# apollo3 register map
Vendor: Ambiq Micro; Series: Apollo; File version: 1.0
CPU: CM4 r1p0, little endian, MPU, FPU, 3 interrupt priority bits
Registers are 32-bit, read-write, reset 0x0 unless marked. A register's access mark holds for its fields unless they carry their own. Offsets are from the block's base; [hi:lo] are bit positions; {n}, {i} and the like mark numbered series; 'fields as' and 'values as' point back to an identical list.

## ADC — Analog Digital Converter Control
Base 0x50010000
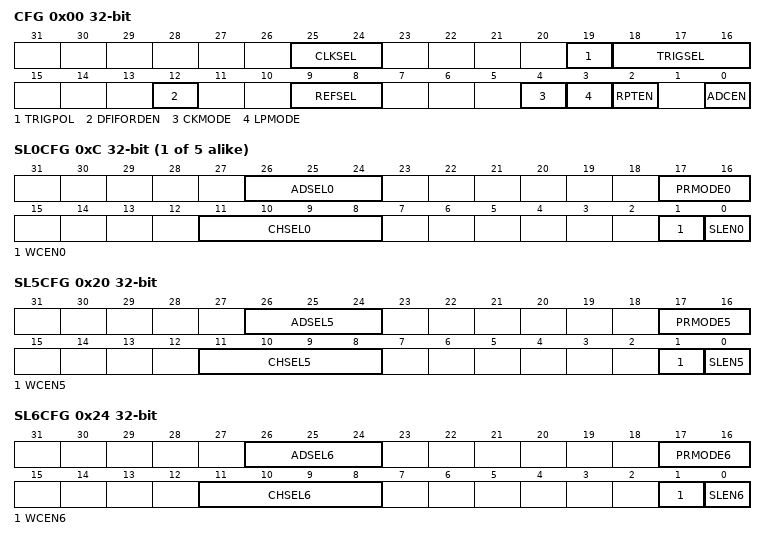
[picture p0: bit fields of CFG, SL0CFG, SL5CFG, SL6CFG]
0x00 CFG — Configuration Register
  [25:24] CLKSEL — Select the source and frequency for the ADC clock. All values not enumerated below are undefined.
    0=OFF (Off mode. The HFRC or HFRC_DIV2 clock must be selected for the ADC to function. The ADC controller automatically shuts off the clock in it's low power modes. When setting ADCEN to '0', the CLKSEL should remain set to one of the two clock selects for proper power down sequencing. value.); 1=HFRC (HFRC Core Clock divided by (CORESEL+1) value.); 2=HFRC_DIV2 (HFRC Core Clock / 2 further divided by (CORESEL+1) value.)
  [19] TRIGPOL — This bit selects the ADC trigger polarity for external off chip triggers.
    0=RISING_EDGE (Trigger on rising edge. value.); 1=FALLING_EDGE (Trigger on falling edge. value.)
  [18:16] TRIGSEL — Select the ADC trigger source.
    {v}=EXT{v} (Off chip External Trigger{v} (ADC_ET{v}) value.) (v=0..3); 4=VCOMP (Voltage Comparator Output value.); 7=SWT (Software Trigger value.)
  [12] DFIFORDEN — Destructive FIFO Read Enable. Setting this will enable FIFO pop upon reading the FIFOPR register.
    0=DIS (Destructive Reads are prevented. Reads to the FIFOPR register will not POP an entry off the FIFO. value.); 1=EN (Reads to the FIFOPR registger will automatically pop an entry off the FIFO. value.)
  [9:8] REFSEL — Select the ADC reference voltage.
    0=INT2P0 (Internal 2.0V Bandgap Reference Voltage value.); 1=INT1P5 (Internal 1.5V Bandgap Reference Voltage value.); 2=EXT2P0 (Off Chip 2.0V Reference value.); 3=EXT1P5 (Off Chip 1.5V Reference value.)
  [4] CKMODE — Clock mode register
    0=LPCKMODE (Disable the clock between scans for LPMODE0. Set LPCKMODE to 0x1 while configuring the ADC. value.); 1=LLCKMODE (Low Latency Clock Mode. When set, HFRC and the adc_clk will remain on while in functioning in LPMODE0. value.)
  [3] LPMODE — Select power mode to enter between active scans.
    0=MODE0 (Low Power Mode 0. Leaves the ADC fully powered between scans with minimum latency between a trigger event and sample data collection. value.); 1=MODE1 (Low Power Mode 1. Powers down all circuity and clocks associated with the ADC until the next trigger event. Between scans, the reference buffer requires up to 50us of delay from a scan trigger event before the conversion will commence while operating in this mode. value.)
  [2] RPTEN — This bit enables Repeating Scan Mode.
    0=SINGLE_SCAN (In Single Scan Mode, the ADC will complete a single scan upon each trigger event. value.); 1=REPEATING_SCAN (In Repeating Scan Mode, the ADC will complete it's first scan upon the initial trigger event and all subsequent scans will occur at regular intervals defined by the configuration programmed for the CTTMRA3 internal timer until the timer is disabled or the ADC is disabled. When disabling the ADC (setting ADCEN to '0'), the RPTEN bit should be cleared. value.)
  [0] ADCEN — This bit enables the ADC module. While the ADC is enabled, the ADCCFG and SLOT Configuration regsiter settings must remain stable and unchanged. All configuration register settings, slot configuration settings and window comparison settings should be written prior to setting the ADCEN bit to '1'.
    0=DIS (Disable the ADC module. value.); 1=EN (Enable the ADC module. value.)
0x04 STAT — ADC Power Status
  [0] PWDSTAT — Indicates the power-status of the ADC.
    0=ON (Powered on. value.); 1=POWERED_DOWN (ADC Low Power Mode 1. value.)
0x08 SWT — Software trigger
  [7:0] SWT — Writing 0x37 to this register generates a software trigger.
    55=GEN_SW_TRIGGER (Writing this value generates a software trigger. value.)
{0xC+4i} SL{i}CFG (i=0..4) — Slot {i} Configuration Register
  [26:24] ADSEL{i} — Select the number of measurements to average in the accumulate divide module for this slot.
    0=AVG_1_MSRMT (Average in 1 measurement in the accumulate divide module for this slot. value.); 1=AVG_2_MSRMTS (Average in 2 measurements in the accumulate divide module for this slot. value.); 2=AVG_4_MSRMTS (Average in 4 measurements in the accumulate divide module for this slot. value.); 3=AVG_8_MSRMT (Average in 8 measurements in the accumulate divide module for this slot. value.); 4=AVG_16_MSRMTS (Average in 16 measurements in the accumulate divide module for this slot. value.); 5=AVG_32_MSRMTS (Average in 32 measurements in the accumulate divide module for this slot. value.); 6=AVG_64_MSRMTS (Average in 64 measurements in the accumulate divide module for this slot. value.); 7=AVG_128_MSRMTS (Average in 128 measurements in the accumulate divide module for this slot. value.)
  [17:16] PRMODE{i} — Set the Precision Mode For Slot.
    0=P14B (14-bit precision mode value.); 1=P12B (12-bit precision mode value.); 2=P10B (10-bit precision mode value.); 3=P8B (8-bit precision mode value.)
  [11:8] CHSEL{i} — Select one of the 14 channel inputs for this slot.
    0=SE0 (single ended external GPIO connection to pad16. value.); 1=SE1 (single ended external GPIO connection to pad29. value.); 2=SE2 (single ended external GPIO connection to pad11. value.); {v}=SE{v} (single ended external GPIO connection to pad{v+28}. value.) (v=3..7); 8=SE8 (single ended external GPIO connection to pad13. value.); 9=SE9 (single ended external GPIO connection to pad12. value.); 10=DF0 (differential external GPIO connections to pad12(N) and pad13(P). value.); 11=DF1 (differential external GPIO connections to pad15(N) and pad14(P). value.); 12=TEMP (internal temperature sensor. value.); 13=BATT (internal voltage divide-by-3 connection. value.); 14=VSS (Input VSS value.)
  [1] WCEN{i} — This bit enables the window compare function for slot {i}.
    1=WCEN (Enable the window compare for slot {i}. value.)
  [0] SLEN{i} — This bit enables slot {i} for ADC conversions.
    1=SLEN (Enable slot {i} for ADC conversions. value.)
0x20 SL5CFG — Slot 5 Configuration Register
  [26:24] ADSEL5 — Select number of measurements to average in the accumulate divide module for this slot.
    values as SL0CFG.ADSEL{i}
  [17:16] PRMODE5 — Set the Precision Mode For Slot.
    values as SL0CFG.PRMODE{i}
  [11:8] CHSEL5 — Select one of the 14 channel inputs for this slot.
    values as SL0CFG.CHSEL{i}
  [1] WCEN5 — This bit enables the window compare function for slot 5.
    1=WCEN (Enable the window compare for slot 5. value.)
  [0] SLEN5 — This bit enables slot 5 for ADC conversions.
    1=SLEN (Enable slot 5 for ADC conversions. value.)
0x24 SL6CFG — Slot 6 Configuration Register
  [26:24] ADSEL6 — Select the number of measurements to average in the accumulate divide module for this slot.
    values as SL0CFG.ADSEL{i}
  [17:16] PRMODE6 — Set the Precision Mode For Slot.
    values as SL0CFG.PRMODE{i}
  [11:8] CHSEL6 — Select one of the 14 channel inputs for this slot.
    values as SL0CFG.CHSEL{i}
  [1] WCEN6 — This bit enables the window compare function for slot 6.
    1=WCEN (Enable the window compare for slot 6. value.)
  [0] SLEN6 — This bit enables slot 6 for ADC conversions.
    1=SLEN (Enable slot 6 for ADC conversions. value.)
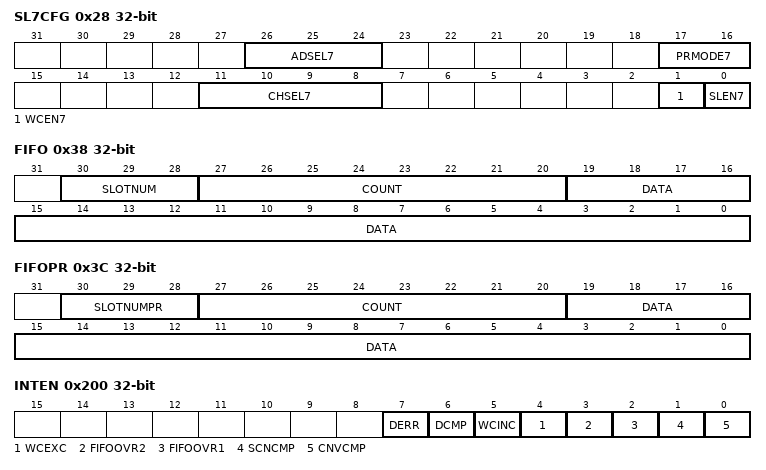
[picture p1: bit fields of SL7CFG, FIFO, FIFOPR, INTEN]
0x28 SL7CFG — Slot 7 Configuration Register
  [26:24] ADSEL7 — Select the number of measurements to average in the accumulate divide module for this slot.
    values as SL0CFG.ADSEL{i}
  [17:16] PRMODE7 — Set the Precision Mode For Slot.
    values as SL0CFG.PRMODE{i}
  [11:8] CHSEL7 — Select one of the 14 channel inputs for this slot.
    values as SL0CFG.CHSEL{i}
  [1] WCEN7 — This bit enables the window compare function for slot 7.
    1=WCEN (Enable the window compare for slot 7. value.)
  [0] SLEN7 — This bit enables slot 7 for ADC conversions.
    1=SLEN (Enable slot 7 for ADC conversions. value.)
0x2C WULIM — Window Comparator Upper Limits Register
  [19:0] ULIM — Sets the upper limit for the window comparator.
0x30 WLLIM — Window Comparator Lower Limits Register
  [19:0] LLIM — Sets the lower limit for the window comparator.
0x34 SCWLIM — Scale Window Comparator Limits
  [0] SCWLIMEN — Scale the window limits compare values per precision mode. When set to 0x0 (default), the values in the 20-bit limits registers will compare directly with the FIFO values regardless of the precision mode the slot is configured to. When set to 0x1, the compare values will be divided by the difference in precision bits while performing the window limit comparisons.
0x38 FIFO — FIFO Data and Valid Count Register
  [30:28] SLOTNUM — Slot number associated with this FIFO data.
  [27:20] COUNT — Number of valid entries in the ADC FIFO.
  [19:0] DATA — Oldest data in the FIFO.
0x3C FIFOPR — FIFO Data and Valid Count Register
  [30:28] SLOTNUMPR — Slot number associated with this FIFO data.
  [27:20] COUNT — Number of valid entries in the ADC FIFO.
  [19:0] DATA — Oldest data in the FIFO.
0x200 INTEN — ADC Interrupt registers: Enable
  [7] DERR — DMA Error Condition
    1=DMAERROR (DMA Error Condition Occurred value.)
  [6] DCMP — DMA Transfer Complete
    1=DMACOMPLETE (DMA Completed a transfer value.)
  [5] WCINC — Window comparator voltage incursion interrupt.
    1=WCINCINT (Window comparitor voltage incursion interrupt. value.)
  [4] WCEXC — Window comparator voltage excursion interrupt.
    1=WCEXCINT (Window comparitor voltage excursion interrupt. value.)
  [3] FIFOOVR2 — FIFO 100 percent full interrupt.
    1=FIFOFULLINT (FIFO 100 percent full interrupt. value.)
  [2] FIFOOVR1 — FIFO 75 percent full interrupt.
    1=FIFO75INT (FIFO 75 percent full interrupt. value.)
  [1] SCNCMP — ADC scan complete interrupt.
    1=SCNCMPINT (ADC scan complete interrupt. value.)
  [0] CNVCMP — ADC conversion complete interrupt.
    1=CNVCMPINT (ADC conversion complete interrupt. value.)
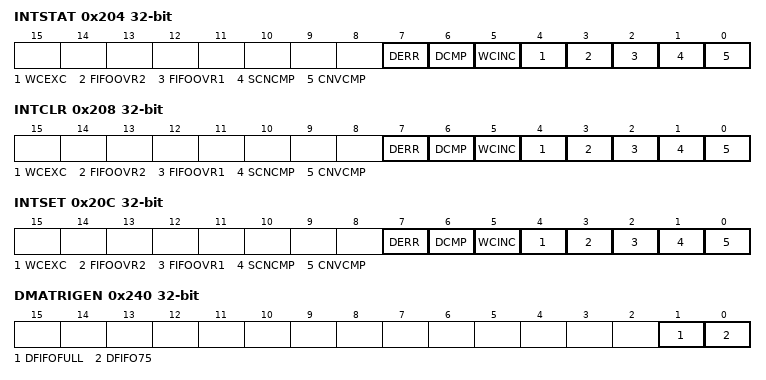
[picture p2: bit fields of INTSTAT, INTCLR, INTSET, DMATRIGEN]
0x204 INTSTAT — ADC Interrupt registers: Status
  fields as INTEN
0x208 INTCLR — ADC Interrupt registers: Clear
  fields as INTEN
0x20C INTSET — ADC Interrupt registers: Set
  fields as INTEN
0x240 DMATRIGEN — DMA Trigger Enable Register
  [1] DFIFOFULL — Trigger DMA upon FIFO 100 percent Full
  [0] DFIFO75 — Trigger DMA upon FIFO 75 percent Full
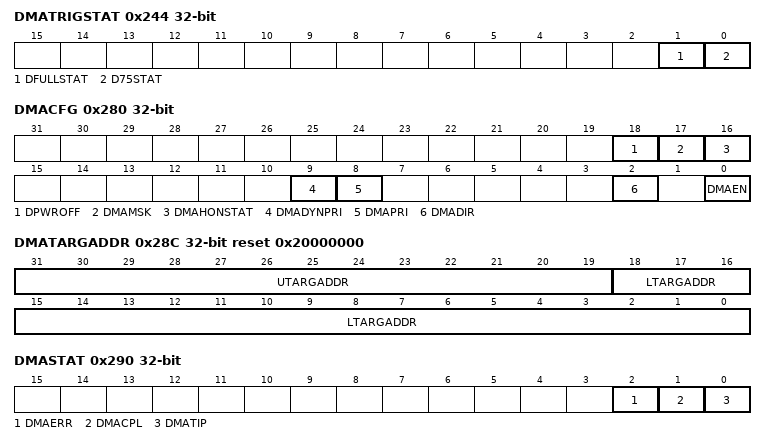
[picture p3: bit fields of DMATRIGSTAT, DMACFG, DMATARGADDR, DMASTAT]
0x244 DMATRIGSTAT — DMA Trigger Status Register
  [1] DFULLSTAT — Triggered DMA from FIFO 100 percent Full
  [0] D75STAT — Triggered DMA from FIFO 75 percent Full
0x280 DMACFG — DMA Configuration Register
  [18] DPWROFF — Power Off the ADC System upon DMACPL.
  [17] DMAMSK — Mask the FIFOCNT and SLOTNUM when transferring FIFO contents to memory
    0=DIS (FIFO Contents are copied directly to memory without modification. value.); 1=EN (Only the FIFODATA contents are copied to memory on DMA transfers. The SLOTNUM and FIFOCNT contents are cleared to zero. value.)
  [16] DMAHONSTAT — Halt New ADC conversions until DMA Status DMAERR and DMACPL Cleared.
    0=DIS (ADC conversions will continue regardless of DMA status register value.); 1=EN (ADC conversions will not progress if DMAERR or DMACPL bits in DMA status register are set. value.)
  [9] DMADYNPRI — Enables dynamic priority based on FIFO fullness. When FIFO is full, priority is automatically set to HIGH. Otherwise, DMAPRI is used.
    0=DIS (Disable dynamic priority (use DMAPRI setting only) value.); 1=EN (Enable dynamic priority value.)
  [8] DMAPRI — Sets the Priority of the DMA request
    0=LOW (Low Priority (service as best effort) value.); 1=HIGH (High Priority (service immediately) value.)
  [2] DMADIR — Direction
    0=P2M (Peripheral to Memory (SRAM) transaction value.); 1=M2P (Memory to Peripheral transaction value.)
  [0] DMAEN — DMA Enable
    0=DIS (Disable DMA Function value.); 1=EN (Enable DMA Function value.)
0x288 DMATOTCOUNT — DMA Total Transfer Count
  [17:2] TOTCOUNT — Total Transfer Count
0x28C DMATARGADDR reset 0x20000000 — DMA Target Address Register
  [31:19] UTARGADDR — SRAM Target
  [18:0] LTARGADDR — DMA Target Address
0x290 DMASTAT — DMA Status Register
  [2] DMAERR — DMA Error
  [1] DMACPL — DMA Transfer Complete
  [0] DMATIP — DMA Transfer In Progress

## Notices in the file
Copyright (C) 2012-2014 ARM Limited. All rights reserved.
Purpose: System Viewer Description (SVD) Example (Schema Version 1.1)
This is a description of a none-existent and incomplete device
for demonstration purposes only.
Redistribution and use in source and binary forms, with or without
modification, are permitted provided that the following conditions are met:
- Redistributions of source code must retain the above copyright
notice, this list of conditions and the following disclaimer.
- Redistributions in binary form must reproduce the above copyright
notice, this list of conditions and the following disclaimer in the
documentation and/or other materials provided with the distribution.
- Neither the name of ARM nor the names of its contributors may be used
to endorse or promote products derived from this software without
specific prior written permission.
THIS SOFTWARE IS PROVIDED BY THE COPYRIGHT HOLDERS AND CONTRIBUTORS "AS IS"
AND ANY EXPRESS OR IMPLIED WARRANTIES, INCLUDING, BUT NOT LIMITED TO, THE
IMPLIED WARRANTIES OF MERCHANTABILITY AND FITNESS FOR A PARTICULAR PURPOSE
ARE DISCLAIMED. IN NO EVENT SHALL COPYRIGHT HOLDERS AND CONTRIBUTORS BE
LIABLE FOR ANY DIRECT, INDIRECT, INCIDENTAL, SPECIAL, EXEMPLARY, OR
CONSEQUENTIAL DAMAGES (INCLUDING, BUT NOT LIMITED TO, PROCUREMENT OF
SUBSTITUTE GOODS OR SERVICES; LOSS OF USE, DATA, OR PROFITS; OR BUSINESS
INTERRUPTION) HOWEVER CAUSED AND ON ANY THEORY OF LIABILITY, WHETHER IN
CONTRACT, STRICT LIABILITY, OR TORT (INCLUDING NEGLIGENCE OR OTHERWISE)
ARISING IN ANY WAY OUT OF THE USE OF THIS SOFTWARE, EVEN IF ADVISED OF THE
POSSIBILITY OF SUCH DAMAGE.
